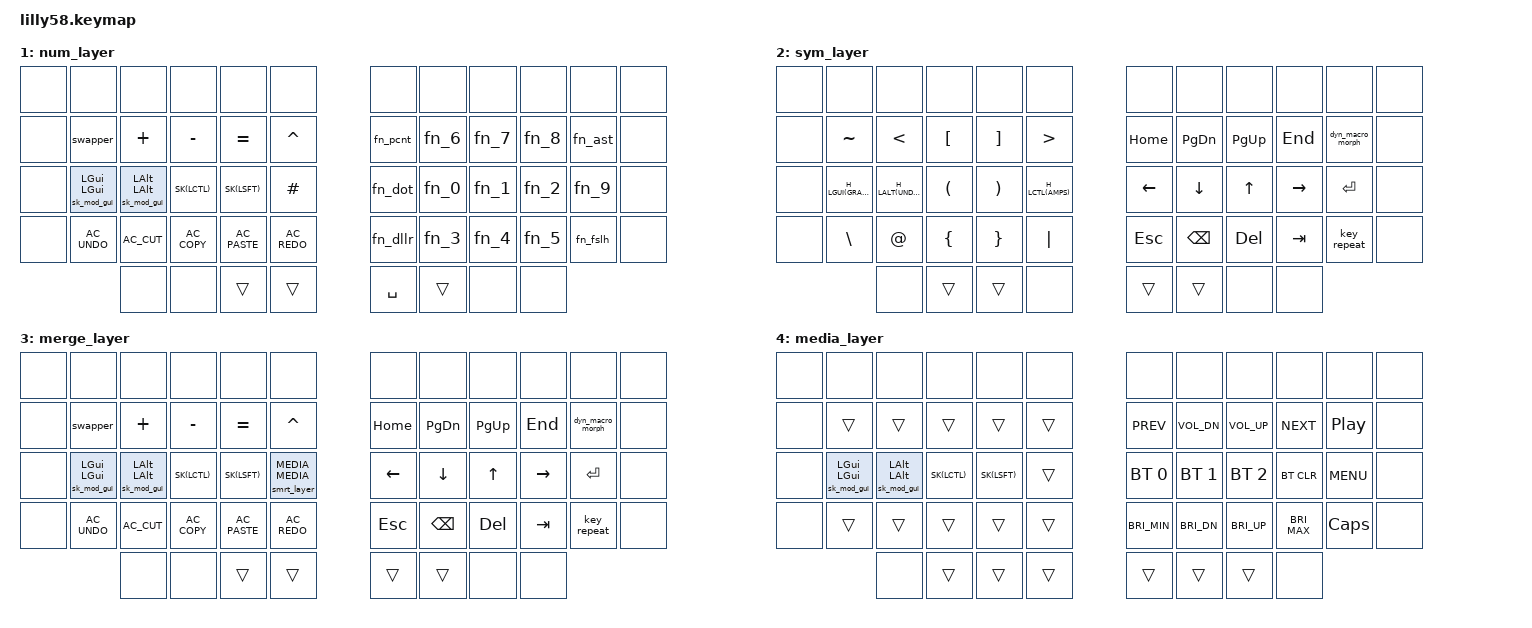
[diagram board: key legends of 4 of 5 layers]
// Copyright (c) 2022 The ZMK Contributors
// SPDX-License-Identifier: MIT

#include "../zmk-nodefree-config/helper.h"
#include "../zmk-nodefree-config/keypos_def/keypos_36keys.h"
#include <behaviors.dtsi>
#include <dt-bindings/zmk/keys.h>
#include <dt-bindings/zmk/bt.h>
#include <dt-bindings/zmk/dynamic-macros.h>

#define XXX &none
#define TODO XXX
#define ___ &trans

#define BASE 0
#define NUM 1
#define SYM 2
#define MERGE 3
#define MEDIA 4

#define S_UNDO &kp C_AC_UNDO
#define S_CUT &kp C_AC_CUT
#define S_COPY &kp C_AC_COPY
#define S_PASTE &kp C_AC_PASTE
#define S_REDO &kp C_AC_REDO

/* ------------------------ general config ----------------------- */
// smart-layer config
&caps_word {  
    /delete-property/ ignore-modifiers; // mods deactivate, requires PR #1451
    /delete-property/ ignore-numbers;
    continue-list = <BACKSPACE ENTER DELETE UNDERSCORE MINUS>;
};
&num_word { 
    layers = <NUM>; // requires PR #1441
    continue-list = <BACKSPACE ENTER DELETE UNDERSCORE MINUS PLUS ASTRK EQUAL FSLH DOT LPAR RPAR HASH DLLR PRCNT CARET LEFT RIGHT UP DOWN>;
};

// key-repeat config
&key_repeat {
    usage-pages = <HID_USAGE_KEY HID_USAGE_CONSUMER>; // repeat all keys
};

// default layer-tap config
&lt {  
    flavor = "balanced";
    tapping-term-ms = <200>;
};

ZMK_CONDITIONAL_LAYER(NUM SYM, MERGE)

/* ---------------------------- special behaviors --------------------------- */
// Alt+Tab swapper, requires PR #1366
ZMK_BEHAVIOR(swapper, tri_state,
    bindings = <&kt LALT>, <&kp TAB>, <&kt LALT>;
    ignored-key-positions = <LM1>; // shift-alt-tab 
)

// dynamci macros, requires PR #1351
ZMK_BEHAVIOR(dyn_macro, dynamic_macro, wait-ms = <10>;)

/* ------------------------------ home row mods ----------------------------- */
// #define KEYS_L LT0 LT1 LT2 LT3 LT4 LM0 LM1 LM2 LM3 LM4 LB0 LB1 LB2 LB3 LB4  // left hand
// #define KEYS_R RT0 RT1 RT2 RT3 RT4 RM0 RM1 RM2 RM3 RM4 RB0 RB1 RB2 RB3 RB4  // right hand
// #define THUMBS LH2 LH1 LH0 RH0 RH1 RH2                                      // thumbs

// // 280, 150
// #define MAKE_HRM(NAME, HOLD, TAP, TRIGGER_POS, EXTRA) \
//     ZMK_BEHAVIOR(NAME, hold_tap, \
//         flavor = "balanced"; \
//         tapping-term-ms = <500>; \
//         quick-tap-ms = <175>; \
//         global-quick-tap-ms = <150>; \
//         bindings = <HOLD>, <TAP>; \
//         hold-trigger-key-positions = <TRIGGER_POS>; \
//         hold-trigger-on-release; \
//         EXTRA \
//     )
// // TODO: potentially only space thumb
// MAKE_HRM(hmlg, &kp, &kp, KEYS_R THUMBS, )  // left-hand HRMs
// MAKE_HRM(hmrg, &kp, &kp, KEYS_L THUMBS, )  // right-hand HRMs
// MAKE_HRM(hml, &kp, &kp, KEYS_R THUMBS, hold-while-undecided;)  // left-hand HRMs
// MAKE_HRM(hmr, &kp, &kp, KEYS_L THUMBS, hold-while-undecided;)  // right-hand HRMs

#define H_LGUI(key) &kp key
#define H_LALT(key) &kp key
#define H_LCTL(key) &kp key
#define H_LSFT(key) &kp key
#define H_RSFT(key) &kp key
#define H_RCTL(key) &kp key
#define H_RALT(key) &kp key
#define H_RGUI(key) &kp key
// #define H_LGUI(key) &hmlg LGUI key 
// #define H_LALT(key) &hmlg LALT key 
// #define H_LCTL(key) &hml LCTL key
// #define H_LSFT(key) &hml LSFT key
// #define H_RSFT(key) &hmr RSFT key
// #define H_RCTL(key) &hmr RCTL key
// #define H_RALT(key) &hmrg RALT key
// #define H_RGUI(key) &hmrg RGUI key

/* --------------------------- sticky key behaviors -------------------------- */
// global config
&sk { // sticky-key
    release-after-ms = <3000>;  // release after timeout
    quick-release;              // no double capitalization when rolling ke
    ignore-modifiers;
    lazy;
};
ZMK_BEHAVIOR(sk_no_lazy, sticky_key, // sticky-key without lazy
    bindings = <&kp>;
    release-after-ms = <3000>;  // release after timeout
    quick-release;              // no double capitalization when rolling keys
    ignore-modifiers;
)
&sl { // sticky-layer 
    release-after-ms = <500>;  // release after timeout
    // This is useful for enabling a layer and then pressing a bunch of sticky keys without leaving the layer. 
    // However, this breaks tapping sl+control+key because it does not exit the layer.
    // ignore-modifiers;
};

// all sticky keys are sticky when tapped, but momentary when held. 
// this allows for rolling layer keys, and accessing modifiers on base, while not getting in the way.
// this behavior is especially useful for use with a mouse because sticky odifiers don't linger
#define STICKY_TAP_MS 200

// tap: sticky-mod | hold: mod
#define SK(mod) &sk_mod mod mod
ZMK_BEHAVIOR(sk_mod, hold_tap,
    flavor = "balanced"; // balanced because we want to consider as tap when rolling
    tapping-term-ms = <STICKY_TAP_MS>; 
    bindings = <&kp>, <&sk>; 
    hold-while-undecided; // requires pr
)
// for GUI/ALT, we don't want to trigger a tap, so we disable hold while undecided
#define SK_LGUI &sk_mod_gui LGUI LGUI 
#define SK_LALT &sk_mod_gui LALT LALT 
ZMK_BEHAVIOR(sk_mod_gui, hold_tap,
    flavor = "balanced"; // balanced because we want to consider as tap when rolling
    tapping-term-ms = <STICKY_TAP_MS>; 
    bindings = <&kp>, <&sk>; 
)

// tap: sticky-shift | hold: shift | shift + tap / double-tap: caps-word 
#define SK_SHFT &sk_shft LSFT LSFT
ZMK_BEHAVIOR(sk_shft, hold_tap,
    flavor = "balanced"; 
    tapping-term-ms = <STICKY_TAP_MS>; 
    bindings = <&kp>, <&smrt_shft_morph>; 
    hold-while-undecided;
) 
ZMK_BEHAVIOR(smrt_shft_morph, mod_morph,
    mods = <(MOD_LSFT)>; // shift + tap: caps word
    bindings = <&sk_no_lazy LSFT>, <&caps_word>; 
) 

// tap: sticky-layer | hold: layer
#define SMRT_SYM &smrt_layer SYM SYM
#define SMRT_MED &smrt_layer MEDIA MEDIA
ZMK_BEHAVIOR(smrt_layer, hold_tap,
    flavor = "hold-preferred"; // in most cases we want to avoid taps
    tapping-term-ms = <STICKY_TAP_MS>; 
    bindings = <&mo>, <&sl>; 
) 

// tap: sticky-num | hold: num | double-tap: num-word | triple-tap: num-lock
#define SMRT_NUM &smrt_num NUM NUM
ZMK_BEHAVIOR(smrt_num, hold_tap,
    flavor = "hold-preferred"; 
    tapping-term-ms = <STICKY_TAP_MS>; 
    bindings = <&mo>, <&num_dance>; 
) 
ZMK_BEHAVIOR(num_dance, tap_dance,
    tapping-term-ms = <300>; 
    bindings = <&sl NUM>, <&num_word>, <&tog NUM>; // todo: to or tog?
)

/* ------------------------------- mod-morphs ------------------------------- */
// tap: comma | shift + tap: semicolon 
ZMK_BEHAVIOR(comma_morph, mod_morph,
    mods = <(MOD_LSFT|MOD_RSFT)>;
    bindings = <&kp COMMA>, <&kp SEMICOLON>;
)
// tap: dot | shift + tap: colon 
ZMK_BEHAVIOR(dot_morph, mod_morph,
    bindings = <&kp DOT>, <&kp COLON>;
    mods = <(MOD_LSFT|MOD_RSFT)>;
)
// tap: qmark | shift + tap: excl
ZMK_BEHAVIOR(qmark_morph, mod_morph,
    bindings = <&kp QMARK>, <&kp EXCL>;
    mods = <(MOD_LSFT|MOD_RSFT)>;
)

// tap: space | shift + tap: dot -> space -> sticky shift
ZMK_BEHAVIOR(spc_morph, mod_morph,
    bindings = <&kp SPACE>, <&dot_spc>;
    mods = <(MOD_LSFT|MOD_RSFT)>;
)
ZMK_BEHAVIOR(dot_spc, macro,
    wait-ms = <5>;
    tap-ms = <5>;
    bindings = <&dot_morph_cancel &kp SPACE &sk LSFT>;
)
ZMK_BEHAVIOR(dot_morph_cancel, mod_morph,
    bindings = <&kp DOT>, <&kp DOT>;
    mods = <(MOD_LSFT|MOD_RSFT)>;
)

// shift + number: fn
ZMK_BEHAVIOR(fn_0, mod_morph, bindings = <&kp N0>, <&kp PSCRN>; mods = <(MOD_LSFT|MOD_RSFT)>;)
ZMK_BEHAVIOR(fn_1, mod_morph, bindings = <&kp N1>, <&kp F1>; mods = <(MOD_LSFT|MOD_RSFT)>;)
ZMK_BEHAVIOR(fn_2, mod_morph, bindings = <&kp N2>, <&kp F2>; mods = <(MOD_LSFT|MOD_RSFT)>;)
ZMK_BEHAVIOR(fn_3, mod_morph, bindings = <&kp N3>, <&kp F3>; mods = <(MOD_LSFT|MOD_RSFT)>;)
ZMK_BEHAVIOR(fn_4, mod_morph, bindings = <&kp N4>, <&kp F4>; mods = <(MOD_LSFT|MOD_RSFT)>;)
ZMK_BEHAVIOR(fn_5, mod_morph, bindings = <&kp N5>, <&kp F5>; mods = <(MOD_LSFT|MOD_RSFT)>;)
ZMK_BEHAVIOR(fn_6, mod_morph, bindings = <&kp N6>, <&kp F6>; mods = <(MOD_LSFT|MOD_RSFT)>;)
ZMK_BEHAVIOR(fn_7, mod_morph, bindings = <&kp N7>, <&kp F7>; mods = <(MOD_LSFT|MOD_RSFT)>;)
ZMK_BEHAVIOR(fn_8, mod_morph, bindings = <&kp N8>, <&kp F8>; mods = <(MOD_LSFT|MOD_RSFT)>;)
ZMK_BEHAVIOR(fn_9, mod_morph, bindings = <&kp N9>, <&kp F9>; mods = <(MOD_LSFT|MOD_RSFT)>;)
ZMK_BEHAVIOR(fn_dllr, mod_morph, bindings = <&kp DLLR>, <&kp F10>; mods = <(MOD_LSFT|MOD_RSFT)>;)
ZMK_BEHAVIOR(fn_dot, mod_morph, bindings = <&kp DOT>, <&kp F11>; mods = <(MOD_LSFT|MOD_RSFT)>;)
ZMK_BEHAVIOR(fn_pcnt, mod_morph, bindings = <&kp PRCNT>, <&kp F12>; mods = <(MOD_LSFT|MOD_RSFT)>;)
ZMK_BEHAVIOR(fn_ast, mod_morph, bindings = <&kp ASTRK>, <&kp INSERT>; mods = <(MOD_LSFT|MOD_RSFT)>;)
ZMK_BEHAVIOR(fn_fslh, mod_morph, bindings = <&kp FSLH>, <&kp CAPS>; mods = <(MOD_LSFT|MOD_RSFT)>;)

// tap: play | shift + tap: record
ZMK_BEHAVIOR(dyn_macro_morph, mod_morph,
    bindings = <&dyn_macro PLAY>, <&dyn_macro RECORD>;
    mods = <(MOD_LSFT|MOD_RSFT)>;
)

/ {
    //chosen {
      //  zmk,matrix_transform = &five_column_transform;
    //};

    keymap {
        compatible = "zmk,keymap";
        default_layer {
        // ------------------------------------------------------------------------------------------------------------
            // |  ESC  |  1  |  2  |  3   |  4   |  5   |                   |  6   |  7    |  8    |  9   |   0   |   -   |
            // |  TAB  |  Q  |  W  |  E   |  R   |  T   |                   |  Y   |  U    |  I    |  O   |   P   |   =   |
            // |  SHIFT |  A  |  S  |  D   |  F   |  G   |                   |  H   |  J    |  K    |  L   |   ;   |   '   |
            // | CTRL |  Z  |  X  |  C   |  V   |  B   |   "["  |  |  "]"  |  N   |  M    |  ,    |  .   |   /   | SHIFT |
            //              | Undefined  | unknown  | Numlayer |  Shift |  | Space | SYMLayer | undefined  | undefined   |

            label = "Base";
            bindings = <
            &kp ESC &kp N1  &kp N2  &kp N3  &kp N4  &kp N5   &kp N6   &kp N7    &kp N8   &kp N9    &kp N0 &kp MINUS
            &kp TAB &kp Q     &kp W     &kp E     &kp R     &kp T     &kp Y    &kp U     &kp I        &kp O      &kp P  &kp EQUAL
            &kp LEFT_SHIFT  H_LGUI(A) H_LALT(S) H_LCTL(D) H_LSFT(F) &kp G     &kp H       H_RSFT(J) H_RCTL(K)    H_RALT(L)  H_RGUI(SEMICOLON) &kp SQT 
            &kp LCTRL   &kp Z   &kp X &kp C   &kp V &kp B &kp LBKT  &kp RBKT  &kp N &kp M  &kp COMMA &kp DOT    &kp FSLH    &kp RIGHT_SHIFT
                               XXX &kp C_MUTE SMRT_NUM SK_SHFT   &spc_morph  SMRT_SYM  XXX XXX
            >;
            sensor-bindings = <&inc_dec_kp C_VOL_UP C_VOL_DN  &inc_dec_kp UP DOWN>;
        };
        num_layer {
            bindings = <
            XXX XXX XXX XXX XXX XXX XXX XXX XXX XXX XXX XXX
            XXX &swapper  &kp PLUS  &kp MINUS  &kp EQUAL  &kp CARET  &fn_pcnt   &fn_6  &fn_7  &fn_8  &fn_ast XXX
            XXX SK_LGUI   SK_LALT   SK(LCTL)   SK(LSFT)   &kp HASH   &fn_dot    &fn_0  &fn_1  &fn_2  &fn_9 XXX
            XXX S_UNDO    S_CUT     S_COPY     S_PASTE    S_REDO     &fn_dllr   &fn_3  &fn_4  &fn_5  &fn_fslh XXX
                            XXX    XXX        ___        ___        &kp SPACE  ___    XXX XXX 
            >;
            sensor-bindings = <&inc_dec_kp C_VOL_UP C_VOL_DN &inc_dec_kp UP DOWN>;
        };
        sym_layer {
            bindings = <
            XXX XXX XXX XXX XXX XXX XXX XXX XXX XXX XXX XXX
            XXX &kp TILDE     &kp LT        &kp LBKT  &kp RBKT  &kp GT        &kp HOME  &kp PG_DN  &kp PG_UP  &kp END    &dyn_macro_morph XXX
            XXX H_LGUI(GRAVE) H_LALT(UNDER) &kp LPAR  &kp RPAR  H_LCTL(AMPS)  &kp LEFT  &kp DOWN   &kp UP     &kp RIGHT  &kp ENTER XXX
            XXX &kp BSLH      &kp AT        &kp LBRC  &kp RBRC  &kp PIPE      &kp ESC   &kp BSPC   &kp DEL    &kp TAB    &key_repeat XXX
                                        XXX ___       ___       XXX           ___       ___        XXX XXX
            >;
            sensor-bindings = <&inc_dec_kp C_VOL_UP C_VOL_DN &inc_dec_kp UP DOWN>;
        };
 
        merge_layer {
            bindings = <
            XXX XXX XXX XXX XXX XXX XXX XXX XXX XXX XXX XXX
            XXX &swapper &kp PLUS  &kp MINUS  &kp EQUAL  &kp CARET  &kp HOME  &kp PG_DN  &kp PG_UP  &kp END    &dyn_macro_morph XXX
            XXX SK_LGUI  SK_LALT   SK(LCTL)   SK(LSFT)   SMRT_MED   &kp LEFT  &kp DOWN   &kp UP     &kp RIGHT  &kp ENTER XXX
            XXX S_UNDO   S_CUT     S_COPY     S_PASTE    S_REDO     &kp ESC   &kp BSPC   &kp DEL    &kp TAB    &key_repeat XXX
                               XXX XXX        ___        ___        ___       ___        XXX XXX
            >;
            sensor-bindings = <&inc_dec_kp C_VOL_UP C_VOL_DN &inc_dec_kp UP DOWN>;
        };

        media_layer {
            bindings = <
            XXX XXX XXX XXX XXX XXX XXX XXX XXX XXX XXX XXX
            XXX ___       ___       ___        ___        ___    &kp C_PREV     &kp C_VOL_DN  &kp C_VOL_UP  &kp C_NEXT     &kp C_PP XXX
            XXX SK_LGUI   SK_LALT   SK(LCTL)   SK(LSFT)   ___    &bt BT_SEL 0   &bt BT_SEL 1  &bt BT_SEL 2  &bt BT_CLR     &kp C_MENU XXX
            XXX ___       ___       ___        ___        ___    &kp C_BRI_MIN  &kp C_BRI_DN  &kp C_BRI_UP  &kp C_BRI_MAX  &kp CAPS XXX
                                XXX ___        ___        ___    ___            ___           ___ XXX
            >;
            sensor-bindings = <&inc_dec_kp C_VOL_UP C_VOL_DN &inc_dec_kp UP DOWN>;
        };
    };
};
    
/* --------------------------------- combos --------------------------------- */
// ╭─────────────────────┬─────────────────────╮
// │ LT4 LT3 LT2 LT1 LT0 │ RT0 RT1 RT2 RT3 RT4 │
// │ LM4 LM3 LM2 LM1 LM0 │ RM0 RM1 RM2 RM3 RM4 │
// │ LB4 LB3 LB2 LB1 LB0 │ RB0 RB1 RB2 RB3 RB4 │
// ╰───────╮ LH2 LH1 LH0 │ RH0 RH1 RH2 ╭───────╯
//         ╰─────────────┴─────────────╯
// use global-quick-tap-ms for combos (requires PR 1387)
#undef COMBO_HOOK
#define COMBO_HOOK global-quick-tap-ms = <50>;
// combos on every layer
#define LAYER_COMBO(name, keypos, bindings, layer) ZMK_COMBO(name, bindings, keypos, layer, 50)
#define GLOBAL_COMBO(name, keypos, bindings) LAYER_COMBO(name, keypos, bindings, ALL)
// GLOBAL_COMBO(bksp, RB1 RB2, &kp BSPC)
// GLOBAL_COMBO(del, RB2 RB3, &kp DEL)
GLOBAL_COMBO(numl, RB3 RB4, &num_word)
GLOBAL_COMBO(dot_spc, LH0 RH0, &dot_spc)

// combos on the numpad
#define NUM_COMBO(name, keypos, bindings) ZMK_COMBO(name, bindings, keypos, NUM, 50)
NUM_COMBO(esc, LT3 LT2, &kp ESC)
NUM_COMBO(tab, LT2 LT1, &kp TAB)
NUM_COMBO(gui, LB3 LB2, &kp LGUI)
NUM_COMBO(ent, LB2 LB1, &kp ENTER)
NUM_COMBO(lpar, LT2 LM2, &kp LPAR)
NUM_COMBO(rpar, LT1 LM1, &kp RPAR)
NUM_COMBO(x, LM3 LB3, &kp X)

// combos on media
#define MEDIA_COMBO(name, keypos, bindings) ZMK_COMBO(name, bindings, keypos, MEDIA, 50)
NUM_COMBO(mute, RT1 RT2, &kp C_MUTE)
NUM_COMBO(display_off, RB1 RB2, &kp C_BKLT_TOG)

// vertical sfb combos
#define VERTICAL_COMBO(keypos, key1, key2) \
    ZMK_BEHAVIOR(macro_vertical_combo_##key1##key2, macro, \
        wait-ms = <20>; \
        tap-ms = <20>; \
        bindings \
            = <&macro_tap &kp key1> \
            , <&macro_press &kp key2> \
            , <&macro_pause_for_release> \
            , <&macro_release &kp key2> \
            ; \
    ) \
    / { \
        combos { \
            compatible = "zmk,combos"; \
            combo_vertical_combo_##key1##key2 { \
                timeout-ms = <40>; \
                layers = <BASE>; \
                key-positions = <keypos>; \
                bindings = <&macro_vertical_combo_##key1##key2>; \
                slow-release;  \
            }; \
        }; \
    };

// disambiguate mashing SFBs
VERTICAL_COMBO(LT3 LM3, R, L)
VERTICAL_COMBO(LT1 LM1, W, S)
VERTICAL_COMBO(LM1 LB1, S, C)
VERTICAL_COMBO(LM1 LM0, G, S)
VERTICAL_COMBO(RM1 RM0, H, Y)
VERTICAL_COMBO(RM1 RB1, P, H)
VERTICAL_COMBO(RT2 RM2, O, A)
VERTICAL_COMBO(RM0 RT0, Y, APOS)
VERTICAL_COMBO(RM4 RT0, I, APOS)

// ANACRON COMBOS
// the macro is used to enable the layer while the combo is held so that other keys
// on the layer can be used while the thumb is still held
#define THUMB_COMBO_GENERAL(thumb_behavior, thumb_param, thumb, combo_layers, keypos, combo_bindings) \
    ZMK_BEHAVIOR(macro_thumb_##thumb_param##_##thumb##_##keypos, macro, \
        wait-ms = <0>; \
        tap-ms = <0>; \
        bindings \
            = <&macro_press thumb_behavior thumb_param> \
            , <&macro_press combo_bindings> \
            , <&macro_pause_for_release> \
            , <&macro_release combo_bindings> \
            , <&macro_release thumb_behavior thumb_param> \
            ; \
    ) \
    / { \
        combos { \
            compatible = "zmk,combos"; \
            combo_thumb_##thumb_param##_##thumb##_##keypos { \
                timeout-ms = <40>; \
                layers = <combo_layers>; \
                key-positions = <thumb keypos>; \
                bindings = <&macro_thumb_##thumb_param##_##thumb##_##keypos>, <&partial_hold_position thumb thumb_behavior thumb_param>; \
                slow-release;  \
                slow-release-positions = <keypos>; \
                COMBO_HOOK \
            }; \
        }; \
    };
#define THUMB_LAYER_COMBO(thumb_param, thumb, combo_layers, keypos, combo_bindings) THUMB_COMBO_GENERAL(&mo, thumb_param, thumb, combo_layers, keypos, combo_bindings)

// right thumb combos with right hand SYM layer
#define SYM_THUMB_COMBO(keypos, bindings) THUMB_LAYER_COMBO(SYM, RH1, BASE NUM, keypos, bindings)
SYM_THUMB_COMBO(RT0, &kp HOME)
SYM_THUMB_COMBO(RT1, &kp PG_DN)
SYM_THUMB_COMBO(RT2, &kp PG_UP)
SYM_THUMB_COMBO(RT3, &kp END)
// SYM_THUMB_COMBO(RT4, XXX)
SYM_THUMB_COMBO(RM0, &kp LEFT)
SYM_THUMB_COMBO(RM1, &kp DOWN)
SYM_THUMB_COMBO(RM2, &kp UP)
SYM_THUMB_COMBO(RM3, &kp RIGHT)
SYM_THUMB_COMBO(RM4, &kp ENTER)
SYM_THUMB_COMBO(RB0, &kp ESC) 
SYM_THUMB_COMBO(RB1, &kp BSPC)
SYM_THUMB_COMBO(RB2, &kp DEL)
SYM_THUMB_COMBO(RB3, &kp TAB)
SYM_THUMB_COMBO(RB4, &key_repeat)

// right thumb combos with left hand SYM layer 
#define SYM_THUMB_CROSS_COMBO(keypos, bindings) THUMB_LAYER_COMBO(SYM, RH1, BASE, keypos, bindings)
SYM_THUMB_CROSS_COMBO(LT4, &kp TILDE)
SYM_THUMB_CROSS_COMBO(LT3, &kp LT)
SYM_THUMB_CROSS_COMBO(LT2, &kp GT)
SYM_THUMB_CROSS_COMBO(LT1, &kp LBKT)
SYM_THUMB_CROSS_COMBO(LT0, &kp RBKT)
SYM_THUMB_CROSS_COMBO(LM4, &kp GRAVE)
SYM_THUMB_CROSS_COMBO(LM3, &kp AMPS)
SYM_THUMB_CROSS_COMBO(LM2, &kp UNDER)
SYM_THUMB_CROSS_COMBO(LM1, &kp LPAR)
SYM_THUMB_CROSS_COMBO(LM0, &kp RPAR)
SYM_THUMB_CROSS_COMBO(LB4, &kp BSLH)
SYM_THUMB_CROSS_COMBO(LB3, &kp PIPE)
SYM_THUMB_CROSS_COMBO(LB2, &kp AT)
SYM_THUMB_CROSS_COMBO(LB1, &kp LBRC)
SYM_THUMB_CROSS_COMBO(LB0, &kp RBRC)

// left thumb combos with left hand NUM layer
#define NUM_THUMB_COMBO(keypos, bindings) THUMB_LAYER_COMBO(NUM, LH1, BASE SYM, keypos, bindings)
NUM_THUMB_COMBO(LT4, &swapper)
NUM_THUMB_COMBO(LT3, &kp PLUS)
NUM_THUMB_COMBO(LT2, &kp MINUS)
NUM_THUMB_COMBO(LT1, &kp EQUAL)
NUM_THUMB_COMBO(LT0, &kp CARET)
NUM_THUMB_COMBO(LM4, SK_LGUI)
NUM_THUMB_COMBO(LM3, SK_LALT)
NUM_THUMB_COMBO(LM2, SK(LCTL))
NUM_THUMB_COMBO(LM1, SK(LSFT))
NUM_THUMB_COMBO(LM0, SMRT_MED)
NUM_THUMB_COMBO(LB4, S_UNDO)
NUM_THUMB_COMBO(LB3, S_CUT)
NUM_THUMB_COMBO(LB2, S_COPY)
NUM_THUMB_COMBO(LB1, S_PASTE)
NUM_THUMB_COMBO(LB0, S_REDO)

// left thumb combos with right hand NUM layer
#define NUM_THUMB_CROSS_COMBO(keypos, bindings) THUMB_LAYER_COMBO(NUM, LH1, BASE, keypos, bindings)
NUM_THUMB_CROSS_COMBO(RT0, &fn_pcnt)
NUM_THUMB_CROSS_COMBO(RT1, &fn_6)
NUM_THUMB_CROSS_COMBO(RT2, &fn_7)
NUM_THUMB_CROSS_COMBO(RT3, &fn_8)
NUM_THUMB_CROSS_COMBO(RT4, &fn_ast)
NUM_THUMB_CROSS_COMBO(RM0, &fn_dot)
NUM_THUMB_CROSS_COMBO(RM1, &fn_0)
NUM_THUMB_CROSS_COMBO(RM2, &fn_1)
NUM_THUMB_CROSS_COMBO(RM3, &fn_2)
NUM_THUMB_CROSS_COMBO(RM4, &fn_9)
NUM_THUMB_CROSS_COMBO(RB0, &fn_dllr)
NUM_THUMB_CROSS_COMBO(RB1, &fn_3)
NUM_THUMB_CROSS_COMBO(RB2, &fn_4)
NUM_THUMB_CROSS_COMBO(RB3, &fn_5)
NUM_THUMB_CROSS_COMBO(RB4, &fn_fslh)

// left thumb combos with both hands BASE layer
#define SHFT_THUMB_COMBO(keypos, bindings) THUMB_COMBO_GENERAL(&kp, LSFT, LH0, BASE, keypos, bindings)
SHFT_THUMB_COMBO(LT4, &kp B)
SHFT_THUMB_COMBO(LT3, &kp L)
SHFT_THUMB_COMBO(LT2, &kp D)
SHFT_THUMB_COMBO(LT1, &kp W)
SHFT_THUMB_COMBO(LT0, &kp Z)
SHFT_THUMB_COMBO(LM4, &kp N)
SHFT_THUMB_COMBO(LM3, &kp R)
SHFT_THUMB_COMBO(LM2, &kp T)
SHFT_THUMB_COMBO(LM1, &kp S)
SHFT_THUMB_COMBO(LM0, &kp G)
SHFT_THUMB_COMBO(LB4, &kp Q)
SHFT_THUMB_COMBO(LB3, &kp X)
SHFT_THUMB_COMBO(LB2, &kp M)
SHFT_THUMB_COMBO(LB1, &kp C)
SHFT_THUMB_COMBO(LB0, &kp V)

SHFT_THUMB_COMBO(RT0, &kp APOS)
SHFT_THUMB_COMBO(RT1, &kp F)
SHFT_THUMB_COMBO(RT2, &kp O)
SHFT_THUMB_COMBO(RT3, &kp U)
SHFT_THUMB_COMBO(RT4, &kp J)
SHFT_THUMB_COMBO(RM0, &kp Y)
SHFT_THUMB_COMBO(RM1, &kp H)
SHFT_THUMB_COMBO(RM2, &kp A)
SHFT_THUMB_COMBO(RM3, &kp E)
SHFT_THUMB_COMBO(RM4, &kp I)
SHFT_THUMB_COMBO(RB0, &kp K)
SHFT_THUMB_COMBO(RB1, &kp P)
SHFT_THUMB_COMBO(RB2, &comma_morph)
SHFT_THUMB_COMBO(RB3, &dot_morph)
SHFT_THUMB_COMBO(RB4, &qmark_morph)

// TODO:
// - Hardware:
//   - fix right encoder
//   - Fix left OLED
// - Conceptual:
//   - Consider mouse layer
//   - Investigate media keys (brightness, display toggle, music)
// - Minor:
//   - Caps word timeout
//   - Fix undo/redo
//   - Hold symbol for double/triple tap?
// - Workflow:
//   - Add text expansion macros
//   - Add programming bigrams
//   - Investigate symbol sfbs. 
//   - Caps word invert shift
// - ZMK:
//   - bug: sticky cancel releases mo layer

// what if re-add CANCEL on mo tap, but only on layer. Motivation, cancel num lock/caps word. Want to tap sym to cancel. 
// caps kebab, double space ends word

// https://getreuer.info/posts/keyboards/select-word/index.html
// maybe patch tap dance to trigger on every tap
